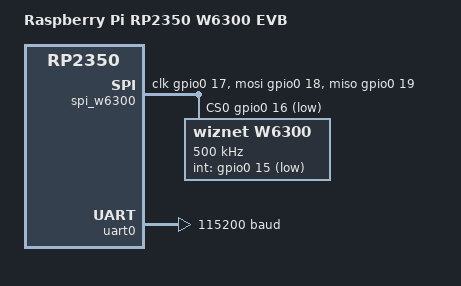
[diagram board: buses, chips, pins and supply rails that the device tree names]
/dts-v1/;

#include <raspberrypi/rpi_pico/rp2350a.dtsi>
#include <riscv/raspberrypi/hazard3.dtsi>

/ {
	model = "Raspberry Pi RP2350 W6300 EVB";
	compatible = "raspberrypi,rp2350-w6300-evb";

	chosen {
		zephyr,sram = &sram0;
		zephyr,flash = &flash0;
		zephyr,console = &uart0;
		zephyr,shell-uart = &uart0;
	};
};

&xosc {
	clock-frequency = <12000000>;
	status = "okay";
};

&gpio0 {
	status = "okay";
};

&flash0 {
	reg = <0x10000000 0x200000>;
};

&uart0 {
	status = "okay";
	current-speed = <115200>;
};

/ {
/* Using software SPI (Bitbang) because pins do not match standard HW SPI0 */
spi_w6300: spi-bitbang {
	compatible = "zephyr,spi-bitbang";
	status = "okay";
	#address-cells = <1>;
	#size-cells = <0>;
	clk-gpios = <&gpio0 17 GPIO_ACTIVE_HIGH>;
	mosi-gpios = <&gpio0 18 GPIO_ACTIVE_HIGH>;
	miso-gpios = <&gpio0 19 GPIO_ACTIVE_HIGH>;
	cs-gpios = <&gpio0 16 GPIO_ACTIVE_LOW>;

	w6300: w6300@0 {
		compatible = "wiznet,w6300";
		reg = <0>;
		spi-max-frequency = <500000>;
		int-gpios = <&gpio0 15 GPIO_ACTIVE_LOW>;
	};
};
};
